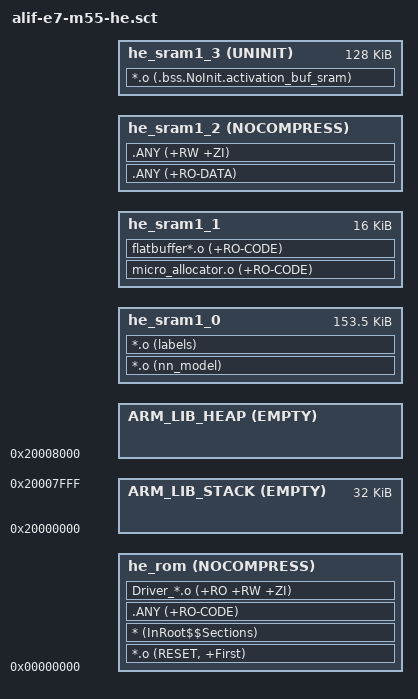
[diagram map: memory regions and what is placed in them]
#! armclang -E --target=arm-arm-none-eabi -mcpu=cortex-m55 -xc
; command above MUST be in first line (no comment above!)
#include "../RTE/Device/AE722F80F55D5TE_M55_HE/M55_HE_map.h"

;  SPDX-FileCopyrightText: Copyright 2022-2023 Arm Limited and/or its
;  affiliates <open-source-office@arm.com>
;  SPDX-License-Identifier: Apache-2.0
;
;  Licensed under the Apache License, Version 2.0 (the "License");
;  you may not use this file except in compliance with the License.
;  You may obtain a copy of the License at
;
;      http://www.apache.org/licenses/LICENSE-2.0
;
;  Unless required by applicable law or agreed to in writing, software
;  distributed under the License is distributed on an "AS IS" BASIS,
;  WITHOUT WARRANTIES OR CONDITIONS OF ANY KIND, either express or implied.
;  See the License for the specific language governing permissions and
;  limitations under the License.
; *************************************************************
; ***       Scatter-Loading Description File                ***
; *************************************************************
;

#define __STACK_SIZE            (0x00008000)
#define __HEAP_SIZE             (SRAM5_SIZE - __STACK_SIZE)

#define ROM_BASE                (0x00000000)
#define RAM_BASE                (0x20000000)
#define STACK_BASE              (RAM_BASE)
#define HEAP_BASE               (RAM_BASE + __STACK_SIZE)

#define SRAM1_USED_BY_HP        (0x001C0000)
#define SRAM1_USABLE_SIZE       (SRAM1_SIZE - SRAM1_USED_BY_HP)

#define MODEL_BASE              (SRAM1_BASE + SRAM1_USED_BY_HP)
#define ARENA_SIZE              (0x00020000)
#define MODEL_SIZE              (0x00026600)
#define SPILL_OVER_CODE_SIZE    (0x00004000)
#define DATA_SIZE               (SRAM1_USABLE_SIZE - (ARENA_SIZE + MODEL_SIZE + SPILL_OVER_CODE_SIZE))


;---------------------------------------------------------
; First load region (ITCM); mapped from SRAM4
;---------------------------------------------------------
LOAD_REGION_0       ROM_BASE                    SRAM4_SIZE
{
    ;-----------------------------------------------------
    ; First part of code mem - 256 kiB
    ;-----------------------------------------------------
    he_rom         ROM_BASE NOCOMPRESS          SRAM4_SIZE
    {
        *.o (RESET, +First)
        * (InRoot$$Sections)
        .ANY (+RO-CODE)
        Driver_*.o (+RO +RW +ZI)
    }

    ;-----------------------------------------------------
    ; Stack - first section in the 256 kiB DTCM (SRAM5)
    ;-----------------------------------------------------
    ARM_LIB_STACK STACK_BASE EMPTY ALIGN 8    __STACK_SIZE
    {}

    ;-----------------------------------------------------
    ; Heap - second section in the 256 kiB DTCM (SRAM5)
    ;-----------------------------------------------------
    ARM_LIB_HEAP  HEAP_BASE  EMPTY ALIGN 8     __HEAP_SIZE
    {}
}

;---------------------------------------------------------
; Second load region (SRAM0)
;---------------------------------------------------------
LOAD_REGION_1       MODEL_BASE           SRAM1_USABLE_SIZE
{
    ;-----------------------------------------------------
    ; SRAM0 space for nn model and input vectors
    ;-----------------------------------------------------
    he_sram1_0     MODEL_BASE ALIGN 16          MODEL_SIZE
    {
        ; nn model
        *.o (nn_model)
        ; labels
        *.o (labels)
    }

    ;-----------------------------------------------------
    ; Spill over R/O code region - SRAM1
    ;-----------------------------------------------------
    he_sram1_1 +0         ALIGNALL 4  SPILL_OVER_CODE_SIZE
    {
        micro_allocator.o (+RO-CODE)
        flatbuffer*.o (+RO-CODE)
    }

    ;-----------------------------------------------------
    ; R/O data and R/W region - SRAM1
    ;-----------------------------------------------------
    he_sram1_2 +0         ALIGNALL 4 NOCOMPRESS  DATA_SIZE
    {
        .ANY        (+RO-DATA)
        .ANY        (+RW +ZI)
    }

    ;-----------------------------------------------------
    ; Second part of SRAM0 used for tensor arena
    ;-----------------------------------------------------
    he_sram1_3 +0 UNINIT ALIGN 16               ARENA_SIZE
    {
        ; activation buffers a.k.a tensor arena
        *.o (.bss.NoInit.activation_buf_sram)
    }
}
